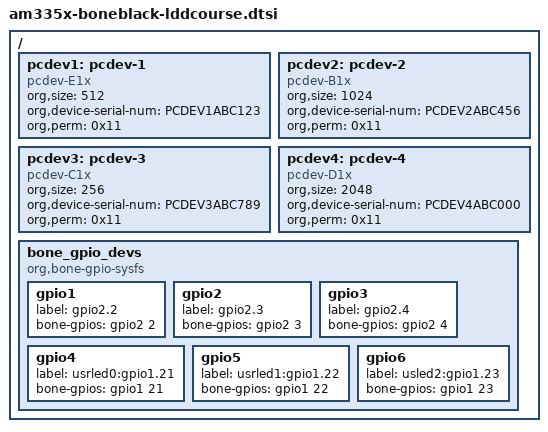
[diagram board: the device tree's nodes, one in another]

/ {
	pcdev1: pcdev-1 {
		compatible = "pcdev-E1x","pcdev-A1x";
		org,size = <512>;
		org,device-serial-num = "PCDEV1ABC123";
		org,perm = <0x11>;
	};
	
	pcdev2: pcdev-2 {
		compatible = "pcdev-B1x";
		org,size = <1024>;
		org,device-serial-num = "PCDEV2ABC456";
		org,perm = <0x11>;
	};

	pcdev3: pcdev-3 {
		compatible = "pcdev-C1x";
		org,size = <256>;
		org,device-serial-num = "PCDEV3ABC789";
		org,perm = <0x11>;
	};
	
	pcdev4: pcdev-4 {
		compatible = "pcdev-D1x";
		org,size = <2048>;
		org,device-serial-num = "PCDEV4ABC000";
		org,perm = <0x11>;
	};

       bone_gpio_devs {
	  
		 compatible = "org,bone-gpio-sysfs";
		
		gpio1 {
			label = "gpio2.2";
			bone-gpios = <&gpio2 2 GPIO_ACTIVE_HIGH>;
				
		};

		gpio2 {
			label = "gpio2.3";
			bone-gpios = <&gpio2 3 GPIO_ACTIVE_HIGH>;
		};
		

		gpio3 {
			label = "gpio2.4";
			bone-gpios = <&gpio2 4 GPIO_ACTIVE_HIGH>;
		};
		

		gpio4 {
			label = "usrled0:gpio1.21";
			bone-gpios = <&gpio1 21 GPIO_ACTIVE_HIGH>;
		};

		gpio5 {
			label = "usrled1:gpio1.22";
			bone-gpios = <&gpio1 22 GPIO_ACTIVE_HIGH>;
		};

		gpio6 {
			label = "usled2:gpio1.23";
			bone-gpios = <&gpio1 23 GPIO_ACTIVE_HIGH>;
		};

	

	};//bone_gpio_devs

}; //root node

